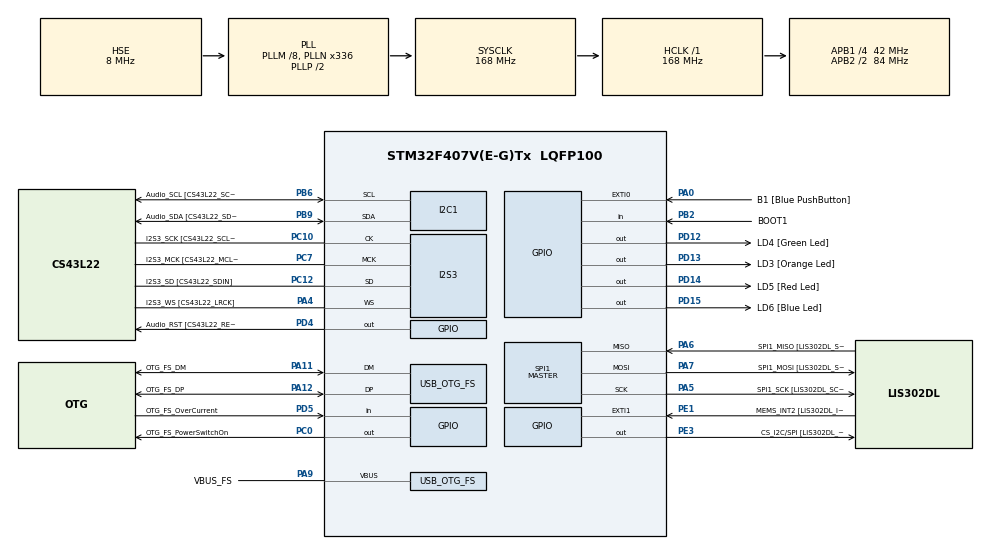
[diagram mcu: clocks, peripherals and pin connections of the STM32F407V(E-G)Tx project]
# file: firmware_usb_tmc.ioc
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Mcu.Family=STM32F4
PA11.GPIO_Speed=GPIO_SPEED_FREQ_LOW
PC3.GPIO_Mode=GPIO_MODE_AF_PP
PD12.GPIO_Label=LD4 [Green Led]
PA6.Mode=Full_Duplex_Master
USB_DEVICE.CLASS_NAME_FS=CDC
PH0-OSC_IN.Signal=RCC_OSC_IN
RCC.CortexFreq_Value=168000000
PC10.GPIO_PuPd=GPIO_NOPULL
PB10.GPIO_Speed=GPIO_SPEED_FREQ_LOW
SPI1.VirtualType=VM_MASTER
PB6.GPIO_Mode=GPIO_MODE_AF_OD
PB10.GPIO_PuPd=GPIO_NOPULL
USB_DEVICE.INTERFACE_STRING_CDC_FS=TMC Interface
PA10.GPIO_PuPd=GPIO_NOPULL
PD15.GPIO_Speed=GPIO_SPEED_FREQ_LOW
PC10.Signal=I2S3_CK
PC12.Signal=I2S3_SD
USB_DEVICE.PID_CDC_FS=0x5740
PA14.GPIO_Label=SWCLK
PA7.GPIO_Mode=GPIO_MODE_AF_PP
PC0.GPIO_Label=OTG_FS_PowerSwitchOn
PA11.Mode=Device_Only
PA6.GPIO_Label=SPI1_MISO [LIS302DL_SDO]
PB6.GPIO_Label=Audio_SCL [CS43L22_SCL]
USB_DEVICE.VirtualMode-CDC_FS=Cdc
PC10.GPIO_Speed=GPIO_SPEED_FREQ_LOW
PA11.GPIO_PuPd=GPIO_NOPULL
PC15-OSC32_OUT.GPIO_Label=PC15-OSC32_OUT
PC3.GPIO_Speed=GPIO_SPEED_FREQ_LOW
RCC.SYSCLKSource=RCC_SYSCLKSOURCE_PLLCLK
ProjectManager.StackSize=0x400
PA6.GPIO_Mode=GPIO_MODE_AF_PP
SPI1.Mode-Full_Duplex_Master=SPI_MODE_MASTER
PD13.Signal=GPIO_Output
PD14.GPIO_Speed=GPIO_SPEED_FREQ_LOW
PA12.Signal=USB_OTG_FS_DP
PA4.Mode=Half_Duplex_Master
SPI1.Direction=SPI_DIRECTION_2LINES
I2S3.AudioFreq-Half_Duplex_Master=I2S_AUDIOFREQ_96K
RCC.HCLKFreq_Value=168000000
PD4.Signal=GPIO_Output
RCC.APB2TimFreq_Value=168000000
PB6.Signal=I2C1_SCL
PC7.Signal=I2S3_MCK
PB6.Mode=I2C
PC3.Signal=I2S2_SD
PE1.Signal=GPXTI1
RCC.AHBFreq_Value=168000000
PH0-OSC_IN.Mode=HSE-External-Oscillator
PH0-OSC_IN.GPIO_Label=PH0-OSC_IN
PA9.GPIO_Mode=GPIO_MODE_INPUT
RCC.HSE_VALUE=8000000
PA4.GPIO_PuPd=GPIO_NOPULL
PB2.Signal=GPIO_Input
PA4.GPIO_Speed=GPIO_SPEED_FREQ_LOW
I2S3.ErrorAudioFreq=-2.34 %
PA6.GPIO_PuPd=GPIO_NOPULL
PC14-OSC32_IN.Mode=LSE-External-Oscillator
PA14.Mode=Serial_Wire
PA5.GPIO_PuPd=GPIO_NOPULL
I2S3.ErrorAudioFreq-Half_Duplex_Master=0.8 %
PA10.GPIO_Label=OTG_FS_ID
PC7.GPIO_Mode=GPIO_MODE_AF_PP
PD5.GPIO_Mode=GPIO_MODE_INPUT
PD14.GPIO_PuPd=GPIO_NOPULL
USB_DEVICE.VID-CDC_FS=0x483
PB2.GPIO_PuPd=GPIO_NOPULL
SPI1.CalculateBaudRate-Full_Duplex_Master=42.0 MBits/s
PH1-OSC_OUT.Mode=HSE-External-Oscillator
PD13.GPIO_Label=LD3 [Orange Led]
Mcu.Package=LQFP100
PB9.Signal=I2C1_SDA
PA6.Signal=SPI1_MISO
PD12.Signal=GPIO_Output
PD5.GPIO_Label=OTG_FS_OverCurrent
NVIC.OTG_FS_IRQn=true\:0\:0\:false\:false\:true\:true\:true
PD15.GPIO_PuPd=GPIO_NOPULL
PA10.Signal=USB_OTG_FS_ID
PB9.GPIO_PuPd=GPIO_NOPULL
USB_OTG_FS.VirtualMode=Device_Only
PA10.GPIO_Speed=GPIO_SPEED_FREQ_LOW
USB_DEVICE.LANGID_STRING-CDC_FS=1036
RCC.APB2CLKDivider=RCC_HCLK_DIV2
PB9.GPIO_Speed=GPIO_SPEED_FREQ_LOW
RCC.APB1TimFreq_Value=84000000
PC14-OSC32_IN.GPIO_Label=PC14-OSC32_IN
PC12.GPIO_PuPd=GPIO_NOPULL
PA6.GPIO_Speed=GPIO_SPEED_FREQ_LOW
PC0.GPIO_PuPd=GPIO_NOPULL
PA12.GPIO_PuPd=GPIO_NOPULL
PA4.GPIO_Label=I2S3_WS [CS43L22_LRCK]
PD15.Signal=GPIO_Output
PC0.PinState=GPIO_PIN_SET
PA12.GPIO_Speed=GPIO_SPEED_FREQ_LOW
PA5.Mode=Full_Duplex_Master
PB3.GPIO_Label=SWO
PC15-OSC32_OUT.Mode=LSE-External-Oscillator
I2S3.FullDuplexMode=I2S_FULLDUPLEXMODE_DISABLE
PD12.GPIO_Speed=GPIO_SPEED_FREQ_LOW
PD15.GPIO_Label=LD6 [Blue Led]
PA7.Mode=Full_Duplex_Master
PB9.GPIO_Label=Audio_SDA [CS43L22_SDA]
PC10.GPIO_Label=I2S3_SCK [CS43L22_SCLK]
USB_DEVICE.VirtualModeFS=Cdc_FS
PA9.GPIO_Label=VBUS_FS
PB6.GPIO_PuPd=GPIO_NOPULL
PC10.Mode=Half_Duplex_Master
PA11.GPIO_Label=OTG_FS_DM
PE1.GPIO_PuPd=GPIO_NOPULL
PD5.Signal=GPIO_Input
PC0.Signal=GPIO_Output
PE1.GPIO_ModeDefaultEXTI=GPIO_MODE_EVT_RISING
RCC.APB1CLKDivider=RCC_HCLK_DIV4
PC14-OSC32_IN.Signal=RCC_OSC32_IN
PA9.GPIO_PuPd=GPIO_NOPULL
PA0-WKUP.GPIO_ModeDefaultEXTI=GPIO_MODE_EVT_RISING
PA12.GPIO_Label=OTG_FS_DP
PA0-WKUP.GPIO_Label=B1 [Blue PushButton]
PA0-WKUP.Signal=GPXTI0
PA10.GPIO_Mode=GPIO_MODE_AF_PP
PA13.Signal=SYS_JTMS-SWDIO
PC10.GPIO_Mode=GPIO_MODE_AF_PP
PD4.GPIO_PuPd=GPIO_NOPULL
PA9.Mode=Activate_VBUS
PC0.GPIO_Speed=GPIO_SPEED_FREQ_LOW
PB10.GPIO_Mode=GPIO_MODE_AF_PP
I2S3.RealAudioFreq-Half_Duplex_Master=96.774 KHz
ProjectManager.TargetToolchain=STM32CubeIDE
PB10.GPIO_Label=CLK_IN [MP45DT02_CLK]
VP_USB_DEVICE_VS_USB_DEVICE_CDC_FS.Mode=CDC_FS
PB9.Mode=I2C
PA9.Signal=USB_OTG_FS_VBUS
I2S3.VirtualMode=I2S_MODE_MASTER
USB_DEVICE.CONFIGURATION_STRING_CDC_FS=TMC Config
PC7.GPIO_PuPd=GPIO_NOPULL
PC15-OSC32_OUT.Signal=RCC_OSC32_OUT
PA7.GPIO_PuPd=GPIO_NOPULL
PB10.Signal=I2S2_CK
PA5.Signal=SPI1_SCK
PC12.Mode=Half_Duplex_Master
board=STM32F407G-DISC1
PD13.GPIO_Speed=GPIO_SPEED_FREQ_LOW
PC7.GPIO_Speed=GPIO_SPEED_FREQ_LOW
RCC.VCOOutputFreq_Value=336000000
PE1.GPIO_Label=MEMS_INT2 [LIS302DL_INT2]
PA7.GPIO_Speed=GPIO_SPEED_FREQ_LOW
PB9.GPIO_Mode=GPIO_MODE_AF_OD
PA12.GPIO_Mode=GPIO_MODE_AF_PP
PA4.GPIO_Mode=GPIO_MODE_AF_PP
RCC.APB2Freq_Value=84000000
PB2.GPIO_Mode=GPIO_MODE_INPUT
SPI1.Mode=SPI_MODE_MASTER
PD4.GPIO_Label=Audio_RST [CS43L22_RESET]
PD4.GPIO_Speed=GPIO_SPEED_FREQ_LOW
PE3.GPIO_PuPd=GPIO_NOPULL
PH1-OSC_OUT.Signal=RCC_OSC_OUT
PD13.GPIO_PuPd=GPIO_NOPULL
PD5.GPIO_PuPd=GPIO_NOPULL
PD14.GPIO_Label=LD5 [Red Led]
PH1-OSC_OUT.GPIO_Label=PH1-OSC_OUT
PA13.Mode=Serial_Wire
Mcu.Name=STM32F407V(E-G)Tx
PA13.GPIO_Label=SWDIO
PC7.GPIO_Label=I2S3_MCK [CS43L22_MCLK]
PD14.Signal=GPIO_Output
RCC.48MHZClocksFreq_Value=48000000
PB3.Signal=SYS_JTDO-SWO
PA4.Signal=I2S3_WS
RCC.SYSCLKFreq_VALUE=168000000
PC12.GPIO_Mode=GPIO_MODE_AF_PP
PA7.GPIO_Label=SPI1_MOSI [LIS302DL_SDA/SDI/SDO]
PA12.Mode=Device_Only
PA5.GPIO_Label=SPI1_SCK [LIS302DL_SCL/SPC]
PE3.GPIO_Speed=GPIO_SPEED_FREQ_LOW
PC12.GPIO_Label=I2S3_SD [CS43L22_SDIN]
PA11.Signal=USB_OTG_FS_DM
PA14.Signal=SYS_JTCK-SWCLK
PB2.GPIO_Label=BOOT1
ProjectManager.HeapSize=0x200
RCC.HSI_VALUE=16000000
PA5.GPIO_Speed=GPIO_SPEED_FREQ_LOW
RCC.PLLQ=7
NVIC.PriorityGroup=NVIC_PRIORITYGROUP_0
I2S3.RealAudioFreq=93.75 KHz
RCC.PLLM=8
RCC.PLLN=336
PE3.Signal=GPIO_Output
PE3.GPIO_Label=CS_I2C/SPI [LIS302DL_CS_I2C/SPI]
PC3.GPIO_Label=PDM_OUT [MP45DT02_DOUT]
PA0-WKUP.GPIO_PuPd=GPIO_NOPULL
I2S3.Instance=SPI$Index
PC7.Mode=Master_Clock_Activated
PA11.GPIO_Mode=GPIO_MODE_AF_PP
PB6.GPIO_Speed=GPIO_SPEED_FREQ_LOW
RCC.APB1Freq_Value=42000000
PA5.GPIO_Mode=GPIO_MODE_AF_PP
PC12.GPIO_Speed=GPIO_SPEED_FREQ_LOW
SPI1.BaudRatePrescaler-Full_Duplex_Master=SPI_BAUDRATEPRESCALER_2
PC3.GPIO_PuPd=GPIO_NOPULL
PD12.GPIO_PuPd=GPIO_NOPULL
PA7.Signal=SPI1_MOSI

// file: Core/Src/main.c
/* USER CODE BEGIN Header */
/**
  ******************************************************************************
  * @file           : main.c
  * @brief          : Main program body
  ******************************************************************************
  * @attention
  *
  * <h2><center>&copy; Copyright (c) 2021 STMicroelectronics.
  * All rights reserved.</center></h2>
  *
  * This software component is licensed by ST under Ultimate Liberty license
  * SLA0044, the "License"; You may not use this file except in compliance with
  * the License. You may obtain a copy of the License at:
  *                             www.st.com/SLA0044
  *
  ******************************************************************************
  */
/* USER CODE END Header */
#include "main.h"
#include "usb_device.h"

/* USER CODE BEGIN Includes */
#include "dscpi.h"
#include "funcgen.h"
/* USER CODE END Includes */

I2C_HandleTypeDef hi2c1;

I2S_HandleTypeDef hi2s3;

SPI_HandleTypeDef hspi1;

void SystemClock_Config(void);
static void MX_GPIO_Init(void);
static void MX_I2C1_Init(void);
static void MX_I2S3_Init(void);
static void MX_SPI1_Init(void);

int main(void)
{

  /* MCU Configuration--------------------------------------------------------*/

  /* Reset of all peripherals, Initializes the Flash interface and the Systick. */
  HAL_Init();

  /* Configure the system clock */
  SystemClock_Config();

  /* Initialize all configured peripherals */
  MX_GPIO_Init();
  MX_I2C1_Init();
  MX_I2S3_Init();
  MX_SPI1_Init();
  MX_USB_DEVICE_Init();

  /* Infinite loop */
  /* USER CODE BEGIN WHILE */

  char our_serial[9];
  our_serial[9] = '\0';
  scpi_init_platform(our_serial);
  while (1)
  {
    /* USER CODE END WHILE */

  }
}

void SystemClock_Config(void)
{
  RCC_OscInitTypeDef RCC_OscInitStruct = {0};
  RCC_ClkInitTypeDef RCC_ClkInitStruct = {0};
  RCC_PeriphCLKInitTypeDef PeriphClkInitStruct = {0};

  /** Configure the main internal regulator output voltage
  */
  __HAL_RCC_PWR_CLK_ENABLE();
  __HAL_PWR_VOLTAGESCALING_CONFIG(PWR_REGULATOR_VOLTAGE_SCALE1);
  /** Initializes the RCC Oscillators according to the specified parameters
  * in the RCC_OscInitTypeDef structure.
  */
  RCC_OscInitStruct.OscillatorType = RCC_OSCILLATORTYPE_HSE;
  RCC_OscInitStruct.HSEState = RCC_HSE_ON;
  RCC_OscInitStruct.PLL.PLLState = RCC_PLL_ON;
  RCC_OscInitStruct.PLL.PLLSource = RCC_PLLSOURCE_HSE;
  RCC_OscInitStruct.PLL.PLLM = 8;
  RCC_OscInitStruct.PLL.PLLN = 336;
  RCC_OscInitStruct.PLL.PLLP = RCC_PLLP_DIV2;
  RCC_OscInitStruct.PLL.PLLQ = 7;
  if (HAL_RCC_OscConfig(&RCC_OscInitStruct) != HAL_OK)
  {
    Error_Handler();
  }
  /** Initializes the CPU, AHB and APB buses clocks
  */
  RCC_ClkInitStruct.ClockType = RCC_CLOCKTYPE_HCLK|RCC_CLOCKTYPE_SYSCLK
                              |RCC_CLOCKTYPE_PCLK1|RCC_CLOCKTYPE_PCLK2;
  RCC_ClkInitStruct.SYSCLKSource = RCC_SYSCLKSOURCE_PLLCLK;
  RCC_ClkInitStruct.AHBCLKDivider = RCC_SYSCLK_DIV1;
  RCC_ClkInitStruct.APB1CLKDivider = RCC_HCLK_DIV4;
  RCC_ClkInitStruct.APB2CLKDivider = RCC_HCLK_DIV2;

  if (HAL_RCC_ClockConfig(&RCC_ClkInitStruct, FLASH_LATENCY_5) != HAL_OK)
  {
    Error_Handler();
  }
  PeriphClkInitStruct.PeriphClockSelection = RCC_PERIPHCLK_I2S;
  PeriphClkInitStruct.PLLI2S.PLLI2SN = 192;
  PeriphClkInitStruct.PLLI2S.PLLI2SR = 2;
  if (HAL_RCCEx_PeriphCLKConfig(&PeriphClkInitStruct) != HAL_OK)
  {
    Error_Handler();
  }
}

static void MX_I2C1_Init(void)
{

  hi2c1.Instance = I2C1;
  hi2c1.Init.ClockSpeed = 100000;
  hi2c1.Init.DutyCycle = I2C_DUTYCYCLE_2;
  hi2c1.Init.OwnAddress1 = 0;
  hi2c1.Init.AddressingMode = I2C_ADDRESSINGMODE_7BIT;
  hi2c1.Init.DualAddressMode = I2C_DUALADDRESS_DISABLE;
  hi2c1.Init.OwnAddress2 = 0;
  hi2c1.Init.GeneralCallMode = I2C_GENERALCALL_DISABLE;
  hi2c1.Init.NoStretchMode = I2C_NOSTRETCH_DISABLE;
  if (HAL_I2C_Init(&hi2c1) != HAL_OK)
  {
    Error_Handler();
  }

}

static void MX_I2S3_Init(void)
{

  hi2s3.Instance = SPI3;
  hi2s3.Init.Mode = I2S_MODE_MASTER_TX;
  hi2s3.Init.Standard = I2S_STANDARD_PHILIPS;
  hi2s3.Init.DataFormat = I2S_DATAFORMAT_16B;
  hi2s3.Init.MCLKOutput = I2S_MCLKOUTPUT_ENABLE;
  hi2s3.Init.AudioFreq = I2S_AUDIOFREQ_96K;
  hi2s3.Init.CPOL = I2S_CPOL_LOW;
  hi2s3.Init.ClockSource = I2S_CLOCK_PLL;
  hi2s3.Init.FullDuplexMode = I2S_FULLDUPLEXMODE_DISABLE;
  if (HAL_I2S_Init(&hi2s3) != HAL_OK)
  {
    Error_Handler();
  }

}

static void MX_SPI1_Init(void)
{

  /* SPI1 parameter configuration*/
  hspi1.Instance = SPI1;
  hspi1.Init.Mode = SPI_MODE_MASTER;
  hspi1.Init.Direction = SPI_DIRECTION_2LINES;
  hspi1.Init.DataSize = SPI_DATASIZE_8BIT;
  hspi1.Init.CLKPolarity = SPI_POLARITY_LOW;
  hspi1.Init.CLKPhase = SPI_PHASE_1EDGE;
  hspi1.Init.NSS = SPI_NSS_SOFT;
  hspi1.Init.BaudRatePrescaler = SPI_BAUDRATEPRESCALER_2;
  hspi1.Init.FirstBit = SPI_FIRSTBIT_MSB;
  hspi1.Init.TIMode = SPI_TIMODE_DISABLE;
  hspi1.Init.CRCCalculation = SPI_CRCCALCULATION_DISABLE;
  hspi1.Init.CRCPolynomial = 10;
  if (HAL_SPI_Init(&hspi1) != HAL_OK)
  {
    Error_Handler();
  }

}

static void MX_GPIO_Init(void)
{
  GPIO_InitTypeDef GPIO_InitStruct = {0};

  /* GPIO Ports Clock Enable */
  __HAL_RCC_GPIOE_CLK_ENABLE();
  __HAL_RCC_GPIOC_CLK_ENABLE();
  __HAL_RCC_GPIOH_CLK_ENABLE();
  __HAL_RCC_GPIOA_CLK_ENABLE();
  __HAL_RCC_GPIOB_CLK_ENABLE();
  __HAL_RCC_GPIOD_CLK_ENABLE();

  /*Configure GPIO pin Output Level */
  HAL_GPIO_WritePin(CS_I2C_SPI_GPIO_Port, CS_I2C_SPI_Pin, GPIO_PIN_RESET);

  /*Configure GPIO pin Output Level */
  HAL_GPIO_WritePin(OTG_FS_PowerSwitchOn_GPIO_Port, OTG_FS_PowerSwitchOn_Pin, GPIO_PIN_SET);

  /*Configure GPIO pin Output Level */
  HAL_GPIO_WritePin(GPIOD, LD4_Pin|LD3_Pin|LD5_Pin|LD6_Pin
                          |Audio_RST_Pin, GPIO_PIN_RESET);

  /*Configure GPIO pin : CS_I2C_SPI_Pin */
  GPIO_InitStruct.Pin = CS_I2C_SPI_Pin;
  GPIO_InitStruct.Mode = GPIO_MODE_OUTPUT_PP;
  GPIO_InitStruct.Pull = GPIO_NOPULL;
  GPIO_InitStruct.Speed = GPIO_SPEED_FREQ_LOW;
  HAL_GPIO_Init(CS_I2C_SPI_GPIO_Port, &GPIO_InitStruct);

  /*Configure GPIO pin : OTG_FS_PowerSwitchOn_Pin */
  GPIO_InitStruct.Pin = OTG_FS_PowerSwitchOn_Pin;
  GPIO_InitStruct.Mode = GPIO_MODE_OUTPUT_PP;
  GPIO_InitStruct.Pull = GPIO_NOPULL;
  GPIO_InitStruct.Speed = GPIO_SPEED_FREQ_LOW;
  HAL_GPIO_Init(OTG_FS_PowerSwitchOn_GPIO_Port, &GPIO_InitStruct);

  /*Configure GPIO pin : PDM_OUT_Pin */
  GPIO_InitStruct.Pin = PDM_OUT_Pin;
  GPIO_InitStruct.Mode = GPIO_MODE_AF_PP;
  GPIO_InitStruct.Pull = GPIO_NOPULL;
  GPIO_InitStruct.Speed = GPIO_SPEED_FREQ_LOW;
  GPIO_InitStruct.Alternate = GPIO_AF5_SPI2;
  HAL_GPIO_Init(PDM_OUT_GPIO_Port, &GPIO_InitStruct);

  /*Configure GPIO pin : B1_Pin */
  GPIO_InitStruct.Pin = B1_Pin;
  GPIO_InitStruct.Mode = GPIO_MODE_EVT_RISING;
  GPIO_InitStruct.Pull = GPIO_NOPULL;
  HAL_GPIO_Init(B1_GPIO_Port, &GPIO_InitStruct);

  /*Configure GPIO pin : BOOT1_Pin */
  GPIO_InitStruct.Pin = BOOT1_Pin;
  GPIO_InitStruct.Mode = GPIO_MODE_INPUT;
  GPIO_InitStruct.Pull = GPIO_NOPULL;
  HAL_GPIO_Init(BOOT1_GPIO_Port, &GPIO_InitStruct);

  /*Configure GPIO pin : CLK_IN_Pin */
  GPIO_InitStruct.Pin = CLK_IN_Pin;
  GPIO_InitStruct.Mode = GPIO_MODE_AF_PP;
  GPIO_InitStruct.Pull = GPIO_NOPULL;
  GPIO_InitStruct.Speed = GPIO_SPEED_FREQ_LOW;
  GPIO_InitStruct.Alternate = GPIO_AF5_SPI2;
  HAL_GPIO_Init(CLK_IN_GPIO_Port, &GPIO_InitStruct);

  /*Configure GPIO pins : LD4_Pin LD3_Pin LD5_Pin LD6_Pin
                           Audio_RST_Pin */
  GPIO_InitStruct.Pin = LD4_Pin|LD3_Pin|LD5_Pin|LD6_Pin
                          |Audio_RST_Pin;
  GPIO_InitStruct.Mode = GPIO_MODE_OUTPUT_PP;
  GPIO_InitStruct.Pull = GPIO_NOPULL;
  GPIO_InitStruct.Speed = GPIO_SPEED_FREQ_LOW;
  HAL_GPIO_Init(GPIOD, &GPIO_InitStruct);

  /*Configure GPIO pin : OTG_FS_OverCurrent_Pin */
  GPIO_InitStruct.Pin = OTG_FS_OverCurrent_Pin;
  GPIO_InitStruct.Mode = GPIO_MODE_INPUT;
  GPIO_InitStruct.Pull = GPIO_NOPULL;
  HAL_GPIO_Init(OTG_FS_OverCurrent_GPIO_Port, &GPIO_InitStruct);

  /*Configure GPIO pin : MEMS_INT2_Pin */
  GPIO_InitStruct.Pin = MEMS_INT2_Pin;
  GPIO_InitStruct.Mode = GPIO_MODE_EVT_RISING;
  GPIO_InitStruct.Pull = GPIO_NOPULL;
  HAL_GPIO_Init(MEMS_INT2_GPIO_Port, &GPIO_InitStruct);

}

void Error_Handler(void)
{
  __disable_irq();
  while (1)
  {
  }
}

/************************ (C) COPYRIGHT STMicroelectronics *****END OF FILE****/
